VERSION "HIPBNYYYYYYYYYYYYYYYYYYYYYYYYYYYYYYYYYYYYY/4/%%%/4/'%**4YYY///"

NS_ :

BS_:

BU_: DBG VCU BMS MCM DCU DAQ S2C

BO_ 256 EMeter_Measurement: 8 Vector__XXX
 SG_ EMeter_Current : 7|32@0- (1.5258789063e-005,0) [0|0] "A" Vector__XXX
 SG_ EMeter_Voltage : 39|32@0- (1.5258789063e-005,0) [0|0] "V" Vector__XXX

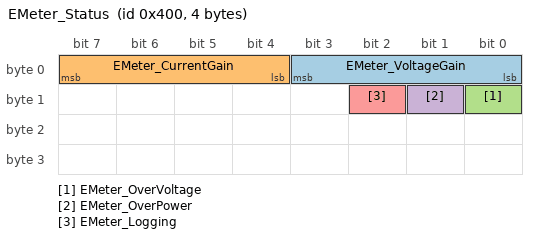
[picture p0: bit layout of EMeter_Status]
BO_ 1024 EMeter_Status: 4 Vector__XXX
 SG_ EMeter_VoltageGain : 3|4@0+ (1,0) [0|0] "bool" Vector__XXX
 SG_ EMeter_CurrentGain : 7|4@0+ (1,0) [0|0] "" Vector__XXX
 SG_ EMeter_OverVoltage : 8|1@0+ (1,0) [0|0] "bool" Vector__XXX
 SG_ EMeter_OverPower : 9|1@0+ (1,0) [0|0] "bool" Vector__XXX
 SG_ EMeter_Logging : 10|1@0+ (1,0) [0|0] "" Vector__XXX
